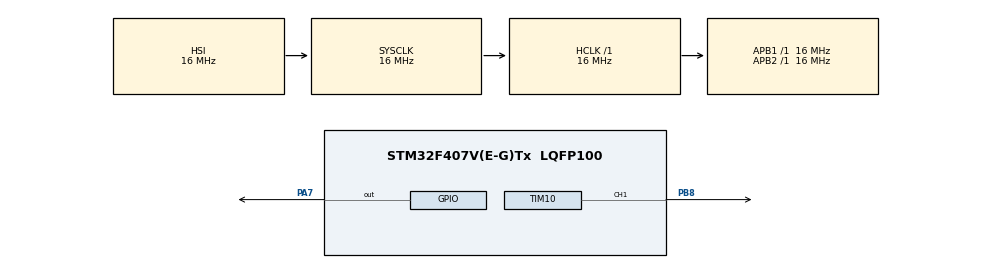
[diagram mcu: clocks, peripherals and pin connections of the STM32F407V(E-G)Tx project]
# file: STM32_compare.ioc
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Mcu.Family=STM32F4
Mcu.Name=STM32F407V(E-G)Tx
Mcu.Package=LQFP100
NVIC.PriorityGroup=NVIC_PRIORITYGROUP_4
PA13.Mode=Serial_Wire
PA13.Signal=SYS_JTMS-SWDIO
PA14.Mode=Serial_Wire
PA14.Signal=SYS_JTCK-SWCLK
PA7.Signal=GPIO_Output
PB8.Signal=S_TIM10_CH1
PH0-OSC_IN.Mode=HSE-External-Oscillator
PH0-OSC_IN.Signal=RCC_OSC_IN
PH1-OSC_OUT.Mode=HSE-External-Oscillator
PH1-OSC_OUT.Signal=RCC_OSC_OUT
ProjectManager.HeapSize=0x200
ProjectManager.StackSize=0x400
ProjectManager.TargetToolchain=STM32CubeIDE
RCC.AHBFreq_Value=16000000
RCC.APB1Freq_Value=16000000
RCC.APB2Freq_Value=16000000
RCC.CortexFreq_Value=16000000
RCC.HSE_VALUE=25000000
RCC.HSI_VALUE=16000000
RCC.LSE_VALUE=32768
RCC.SYSCLKFreq_VALUE=16000000
RCC.VCOOutputFreq_Value=192000000
SH.S_TIM10_CH1.0=TIM10_CH1,Output Compare1 CH1
TIM10.AutoReloadPreload=TIM_AUTORELOAD_PRELOAD_ENABLE
TIM10.Channel=TIM_CHANNEL_1
TIM10.OC1Preload=ENABLE
TIM10.OCMode_1=TIM_OCMODE_TOGGLE
TIM10.Period=999
TIM10.Prescaler=15999
TIM10.Pulse=500
VP_TIM10_VS_ClockSourceINT.Mode=Enable_Timer
board=custom

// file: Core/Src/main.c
/* USER CODE BEGIN Header */
/**
  ******************************************************************************
  * @file           : main.c
  * @brief          : Main program body
  ******************************************************************************
  * @attention
  *
  * Copyright (c) 2025 STMicroelectronics.
  * All rights reserved.
  *
  * This software is licensed under terms that can be found in the LICENSE file
  * in the root directory of this software component.
  * If no LICENSE file comes with this software, it is provided AS-IS.
  *
  ******************************************************************************
  */
/* USER CODE END Header */
#include "main.h"

TIM_HandleTypeDef htim10;

void SystemClock_Config(void);
static void MX_GPIO_Init(void);
static void MX_TIM10_Init(void);

int main(void)
{

  /* MCU Configuration--------------------------------------------------------*/

  /* Reset of all peripherals, Initializes the Flash interface and the Systick. */
  HAL_Init();

  /* Configure the system clock */
  SystemClock_Config();

  /* Initialize all configured peripherals */
  MX_GPIO_Init();
  MX_TIM10_Init();
  /* USER CODE BEGIN 2 */
HAL_TIM_OC_Start(&htim10, TIM_CHANNEL_1);
  /* USER CODE END 2 */

  /* Infinite loop */
  while (1)
  {

  }
}

void SystemClock_Config(void)
{
  RCC_OscInitTypeDef RCC_OscInitStruct = {0};
  RCC_ClkInitTypeDef RCC_ClkInitStruct = {0};

  /** Configure the main internal regulator output voltage
  */
  __HAL_RCC_PWR_CLK_ENABLE();
  __HAL_PWR_VOLTAGESCALING_CONFIG(PWR_REGULATOR_VOLTAGE_SCALE1);

  /** Initializes the RCC Oscillators according to the specified parameters
  * in the RCC_OscInitTypeDef structure.
  */
  RCC_OscInitStruct.OscillatorType = RCC_OSCILLATORTYPE_HSI;
  RCC_OscInitStruct.HSIState = RCC_HSI_ON;
  RCC_OscInitStruct.HSICalibrationValue = RCC_HSICALIBRATION_DEFAULT;
  RCC_OscInitStruct.PLL.PLLState = RCC_PLL_NONE;
  if (HAL_RCC_OscConfig(&RCC_OscInitStruct) != HAL_OK)
  {
    Error_Handler();
  }

  /** Initializes the CPU, AHB and APB buses clocks
  */
  RCC_ClkInitStruct.ClockType = RCC_CLOCKTYPE_HCLK|RCC_CLOCKTYPE_SYSCLK
                              |RCC_CLOCKTYPE_PCLK1|RCC_CLOCKTYPE_PCLK2;
  RCC_ClkInitStruct.SYSCLKSource = RCC_SYSCLKSOURCE_HSI;
  RCC_ClkInitStruct.AHBCLKDivider = RCC_SYSCLK_DIV1;
  RCC_ClkInitStruct.APB1CLKDivider = RCC_HCLK_DIV1;
  RCC_ClkInitStruct.APB2CLKDivider = RCC_HCLK_DIV1;

  if (HAL_RCC_ClockConfig(&RCC_ClkInitStruct, FLASH_LATENCY_0) != HAL_OK)
  {
    Error_Handler();
  }
}

static void MX_TIM10_Init(void)
{

  TIM_OC_InitTypeDef sConfigOC = {0};

  htim10.Instance = TIM10;
  htim10.Init.Prescaler = 15999;
  htim10.Init.CounterMode = TIM_COUNTERMODE_UP;
  htim10.Init.Period = 999;
  htim10.Init.ClockDivision = TIM_CLOCKDIVISION_DIV1;
  htim10.Init.AutoReloadPreload = TIM_AUTORELOAD_PRELOAD_ENABLE;
  if (HAL_TIM_Base_Init(&htim10) != HAL_OK)
  {
    Error_Handler();
  }
  if (HAL_TIM_OC_Init(&htim10) != HAL_OK)
  {
    Error_Handler();
  }
  sConfigOC.OCMode = TIM_OCMODE_TOGGLE;
  sConfigOC.Pulse = 500;
  sConfigOC.OCPolarity = TIM_OCPOLARITY_HIGH;
  sConfigOC.OCFastMode = TIM_OCFAST_DISABLE;
  if (HAL_TIM_OC_ConfigChannel(&htim10, &sConfigOC, TIM_CHANNEL_1) != HAL_OK)
  {
    Error_Handler();
  }
  __HAL_TIM_ENABLE_OCxPRELOAD(&htim10, TIM_CHANNEL_1);
  HAL_TIM_MspPostInit(&htim10);

}

static void MX_GPIO_Init(void)
{
  GPIO_InitTypeDef GPIO_InitStruct = {0};

  /* GPIO Ports Clock Enable */
  __HAL_RCC_GPIOH_CLK_ENABLE();
  __HAL_RCC_GPIOA_CLK_ENABLE();
  __HAL_RCC_GPIOB_CLK_ENABLE();

  /*Configure GPIO pin Output Level */
  HAL_GPIO_WritePin(GPIOA, GPIO_PIN_7, GPIO_PIN_RESET);

  /*Configure GPIO pin : PA7 */
  GPIO_InitStruct.Pin = GPIO_PIN_7;
  GPIO_InitStruct.Mode = GPIO_MODE_OUTPUT_PP;
  GPIO_InitStruct.Pull = GPIO_NOPULL;
  GPIO_InitStruct.Speed = GPIO_SPEED_FREQ_LOW;
  HAL_GPIO_Init(GPIOA, &GPIO_InitStruct);

}

void Error_Handler(void)
{
  __disable_irq();
  while (1)
  {
  }
}
